# STM32WL5x_CM0P register map
File version: 1.9
CPU: CM0 r0p1, little endian, MPU, no FPU, 4 interrupt priority bits
Registers are 32-bit, read-write, reset 0x0 unless marked. A register's access mark holds for its fields unless they carry their own. Offsets are from the block's base; [hi:lo] are bit positions; {n}, {i} and the like mark numbered series.

## TIM17 — General-purpose timers
Base 0x40014800
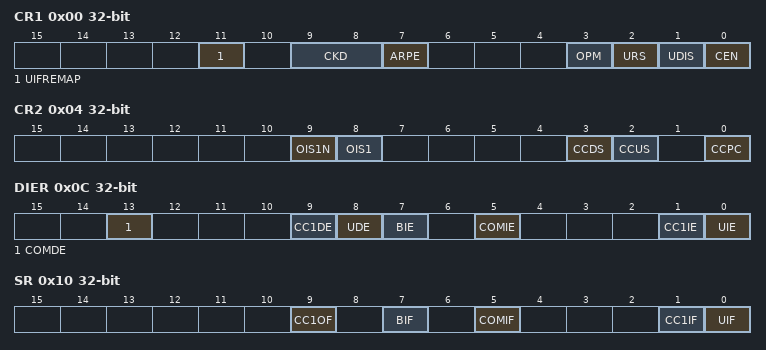
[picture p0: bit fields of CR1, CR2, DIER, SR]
0x00 CR1 — TIM16/TIM17 control register 1
  [11] UIFREMAP — UIF status bit remapping
  [9:8] CKD — Clock division
  [7] ARPE — Auto-reload preload enable
  [3] OPM — One pulse mode
  [2] URS — Update request source
  [1] UDIS — Update disable
  [0] CEN — Counter enable
0x04 CR2 — TIM16/TIM17 control register 2
  [9] OIS1N, [8] OIS1, [3] CCDS, [2] CCUS, [0] CCPC
0x0C DIER — TIM16/TIM17 DMA/interrupt enable register
  [13] COMDE — COM DMA request enable
  [9] CC1DE — Capture/Compare 1 DMA request enable
  [8] UDE — Update DMA request enable
  [7] BIE — Break interrupt enable
  [5] COMIE — COM interrupt enable
  [1] CC1IE — Capture/Compare 1 interrupt enable
  [0] UIE — Update interrupt enable
0x10 SR — TIM16/TIM17 status register
  [9] CC1OF — Capture/Compare 1 overcapture flag
  [7] BIF — Break interrupt flag
  [5] COMIF — COM interrupt flag
  [1] CC1IF — Capture/Compare 1 interrupt flag
  [0] UIF — Update interrupt flag
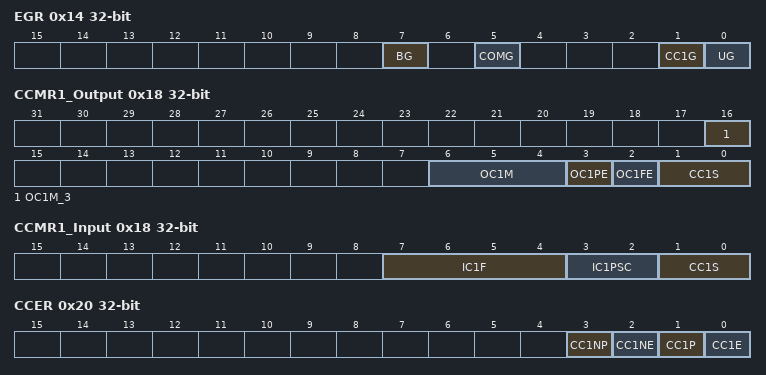
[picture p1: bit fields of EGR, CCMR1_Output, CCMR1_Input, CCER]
0x14 EGR wo — TIM16/TIM17 event generation register
  [7] BG — Break generation
  [5] COMG — Capture/Compare control update generation
  [1] CC1G — Capture/Compare 1 generation
  [0] UG — Update generation
0x18 CCMR1_Output — TIM16/TIM17 capture/compare mode register 1
  [16] OC1M_3 — OC1M
  [6:4] OC1M
  [3] OC1PE
  [2] OC1FE
  [1:0] CC1S
0x18 CCMR1_Input (alternate view of CCMR1_Output) — TIM16/TIM17 capture/compare mode register 1
  [7:4] IC1F, [3:2] IC1PSC, [1:0] CC1S
0x20 CCER — TIM16/TIM17 capture/compare enable register
  [3] CC1NP — Capture/Compare 1 complementary output polarity
  [2] CC1NE — Capture/Compare 1 complementary output enable
  [1] CC1P — Capture/Compare 1 output polarity
  [0] CC1E — Capture/Compare 1 output enable
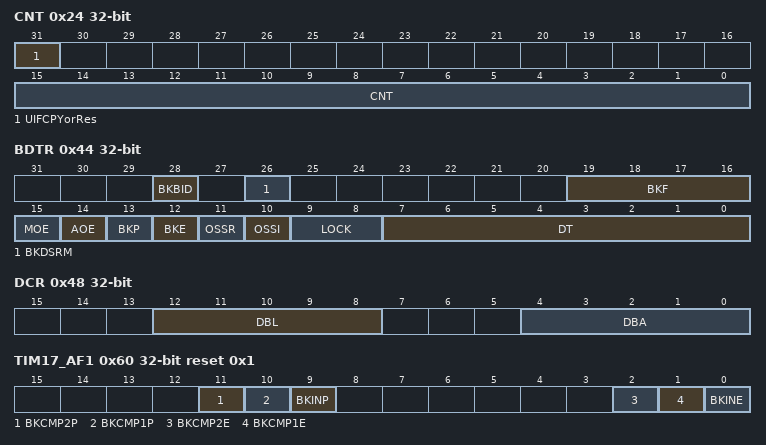
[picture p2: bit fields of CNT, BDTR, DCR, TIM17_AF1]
0x24 CNT access per field — TIM16/TIM17 counter
  [31] UIFCPYorRes ro — UIF Copy
  [15:0] CNT rw
0x28 PSC — TIM16/TIM17 prescaler
  [15:0] PSC — Prescaler value
0x2C ARR reset 0xFFFF — TIM16/TIM17 auto-reload register
  [15:0] ARR — Auto-reload value
0x30 RCR — TIM16/TIM17 repetition counter register
  [7:0] REP — Repetition counter value
0x34 CCR1 — TIM16/TIM17 capture/compare register 1
  [15:0] CCR1 — Capture/Compare 1 value
0x44 BDTR — TIM16/TIM17 break and dead-time register
  [28] BKBID — Break Bidirectional
  [26] BKDSRM — Break Disarm
  [19:16] BKF — Break filter
  [15] MOE — Main output enable
  [14] AOE — Automatic output enable
  [13] BKP — Break polarity
  [12] BKE — Break enable
  [11] OSSR — Off-state selection for Run mode
  [10] OSSI — Off-state selection for Idle mode
  [9:8] LOCK — Lock configuration
  [7:0] DT — Dead-time generator setup
0x48 DCR — TIM16/TIM17 DMA control register
  [12:8] DBL — DMA burst length
  [4:0] DBA — DMA base address
0x4C DMAR — TIM16/TIM17 DMA address for full transfer
  [15:0] DMAB — DMA register for burst accesses
0x50 TIM17_OR1 — TIM17 option register 1
  [1:0] TI1_RMP — Timer 17 input 1 connection
0x60 TIM17_AF1 reset 0x1 — TIM17 alternate function register 1
  [11] BKCMP2P — BRK COMP2 input polarity
  [10] BKCMP1P — BRK COMP1 input polarity
  [9] BKINP — BRK BKIN input polarity
  [2] BKCMP2E — BRK COMP2 enable
  [1] BKCMP1E — BRK COMP1 enable
  [0] BKINE — BRK BKIN input enable
0x68 TIM17_TISEL — TIM17 input selection register
  [3:0] TISEL

## TZIC — TrustZone Interrupt Control
Base 0x58004800
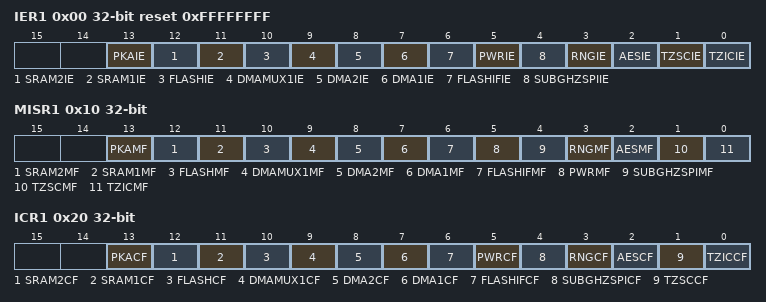
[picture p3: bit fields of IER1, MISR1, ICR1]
0x00 IER1 reset 0xFFFFFFFF — TZIC interrupt enable register 1
  [13] PKAIE, [12] SRAM2IE, [11] SRAM1IE, [10] FLASHIE, [9] DMAMUX1IE, [8] DMA2IE, [7] DMA1IE, [6] FLASHIFIE, [5] PWRIE, [4] SUBGHZSPIIE, [3] RNGIE, [2] AESIE, [1] TZSCIE, [0] TZICIE
0x10 MISR1 ro — TZIC status register 1
  [13] PKAMF, [12] SRAM2MF, [11] SRAM1MF, [10] FLASHMF, [9] DMAMUX1MF, [8] DMA2MF, [7] DMA1MF, [6] FLASHIFMF, [5] PWRMF, [4] SUBGHZSPIMF, [3] RNGMF, [2] AESMF, [1] TZSCMF, [0] TZICMF
0x20 ICR1 — TZIC interrupt status clear register 1
  [13] PKACF, [12] SRAM2CF, [11] SRAM1CF, [10] FLASHCF, [9] DMAMUX1CF, [8] DMA2CF, [7] DMA1CF, [6] FLASHIFCF, [5] PWRCF, [4] SUBGHZSPICF, [3] RNGCF, [2] AESCF, [1] TZSCCF, [0] TZICCF

## TZSC — Global TrustZone Controller
Base 0x58004400
0x00 TZSC_CR — TZSC control register
  [0] LCK
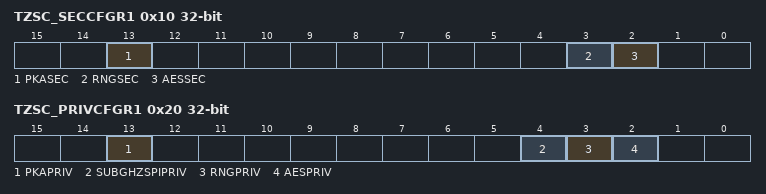
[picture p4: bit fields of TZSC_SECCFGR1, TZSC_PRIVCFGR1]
0x10 TZSC_SECCFGR1 — TZSC security configuration register
  [13] PKASEC, [3] RNGSEC, [2] AESSEC
0x20 TZSC_PRIVCFGR1 — TZSC privilege configuration register 1
  [13] PKAPRIV, [4] SUBGHZSPIPRIV, [3] RNGPRIV, [2] AESPRIV
{0x128+8i} TZSC_MPCWM{i}_UPWMR reset 0xFFF0000 (i=1..3) — Unprivileged Water Mark {i} register
  [27:16] LGTH
0x134 TZSC_MPCWM1_UPWWMR reset 0xFFF0000 — Unprivileged Writable Water Mark 1 register
  [27:16] LGTH — Define the length of Flash Unprivileged Writable area, in 2

## VREFBUF — Voltage reference buffer
Base 0x40010030
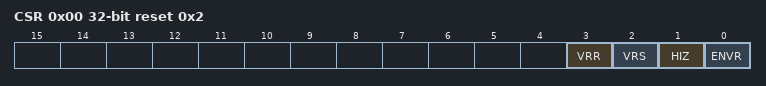
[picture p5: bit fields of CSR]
0x00 CSR access per field reset 0x2 — control and status register
  [3] VRR ro — Voltage reference buffer ready
  [2] VRS rw — Voltage reference scale
  [1] HIZ rw — High impedance mode
  [0] ENVR rw — Voltage reference buffer mode enable
0x04 CCR — calibration control register
  [5:0] TRIM — Trimming code

## WWDG — System window watchdog
Base 0x40002C00
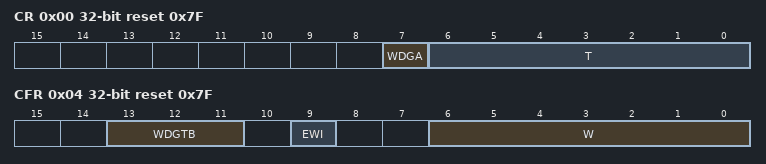
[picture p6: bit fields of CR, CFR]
0x00 CR reset 0x7F — Control register
  [7] WDGA — Activation bit
  [6:0] T — 7-bit counter (MSB to LSB)
0x04 CFR access per field reset 0x7F — Configuration register
  [13:11] WDGTB rw — Timer base
  [9] EWI wo — Early wakeup interrupt
  [6:0] W rw — 7-bit window value
0x08 SR — Status register
  [0] EWIF — Early wakeup interrupt flag
